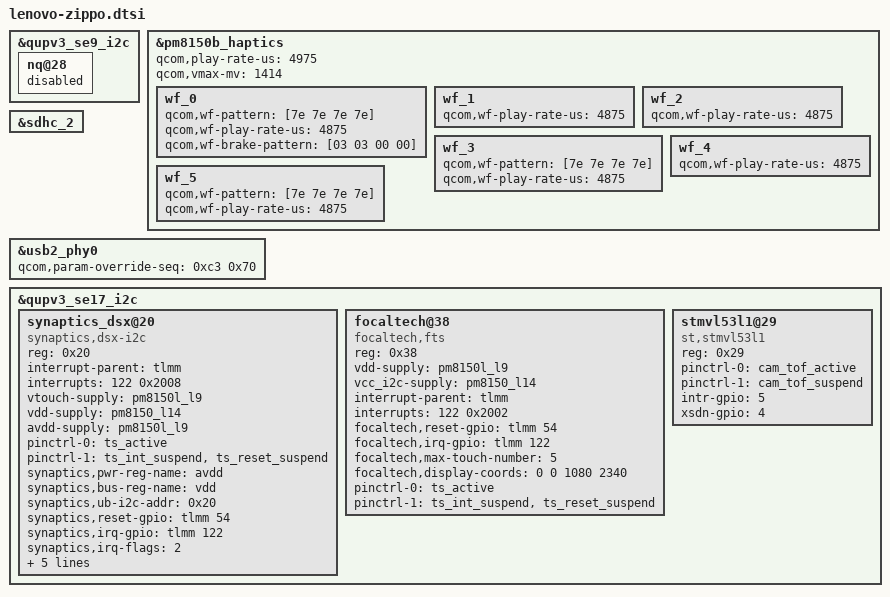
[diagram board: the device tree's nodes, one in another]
/* Copyright (c) 2016-2017, The Linux Foundation. All rights reserved.
 *
 * This program is free software; you can redistribute it and/or modify
 * it under the terms of the GNU General Public License version 2 and
 * only version 2 as published by the Free Software Foundation.
 *
 * This program is distributed in the hope that it will be useful,
 * but WITHOUT ANY WARRANTY; without even the implied warranty of
 * MERCHANTABILITY or FITNESS FOR A PARTICULAR PURPOSE.  See the
 * GNU General Public License for more details.
 */

#include "../common/lenovo-heart-goodixfp.dtsi"

/*Zippo do not support NFC*/
&qupv3_se9_i2c {
	nq@28 {
		status = "disabled";
	};
};

&pm8150b_haptics {
	qcom,play-rate-us = <4975>;
	qcom,vmax-mv = <1414>;

	wf_0 {
		/* CLICK */
		/delete-property/qcom,lra-auto-resonance-disable;
		qcom,wf-pattern = [7e 7e 7e 7e];
		qcom,wf-play-rate-us = <4875>;
		qcom,wf-brake-pattern = [03 03 00 00];
	};
	wf_1 {
		/* DOUBLE CLICK */
		/delete-property/qcom,lra-auto-resonance-disable;
		qcom,wf-play-rate-us = <4875>;
	};
	wf_2 {
		/* TICK */
		/delete-property/qcom,lra-auto-resonance-disable;
		qcom,wf-play-rate-us = <4875>;
	};
	wf_3 {
		/* THUD */
		/delete-property/qcom,lra-auto-resonance-disable;
		qcom,wf-pattern = [7e 7e 7e 7e];
		qcom,wf-play-rate-us = <4875>;
	};
	wf_4 {
		/* POP */
		/delete-property/qcom,lra-auto-resonance-disable;
		qcom,wf-play-rate-us = <4875>;
	};
	wf_5 {
		/* HEAVY CLICK */
		/delete-property/qcom,lra-auto-resonance-disable;
		qcom,wf-pattern = [7e 7e 7e 7e];
		qcom,wf-play-rate-us = <4875>;
	};
};
&sdhc_2 {
	status = "ok";
};

&usb2_phy0 {
	qcom,param-override-seq = <0xc3 0x70>;
};

&qupv3_se17_i2c {
	status = "ok";

	synaptics_dsx@20 {
		compatible = "synaptics,dsx-i2c";
		reg = <0x20>;
		status = "ok";
		interrupt-parent = <&tlmm>;
		interrupts = <122 0x2008>;
		vtouch-supply = <&pm8150l_l9>;
		vdd-supply = <&pm8150_l14>;
		avdd-supply = <&pm8150l_l9>;
		pinctrl-names = "pmx_ts_active","pmx_ts_suspend";
		pinctrl-0 = <&ts_active>;
		pinctrl-1 = <&ts_int_suspend &ts_reset_suspend>;
		synaptics,pwr-reg-name = "avdd";
		synaptics,bus-reg-name = "vdd";
		synaptics,ub-i2c-addr = <0x20>;
		synaptics,reset-gpio = <&tlmm 54 0x0>;
		synaptics,irq-gpio = <&tlmm 122 0x2008>;
		synaptics,irq-flags = <2>; /* 1:trigger rising, 2:trigger falling;*/
		synaptics,irq-on-state = <0>;
		synaptics,power-delay-ms = <200>;
		synaptics,reset-delay-ms = <200>;
		synaptics,reset-on-state = <0>;
		synaptics,reset-active-ms = <20>;
		/* synaptics,swap-axes; */
		/* uncomment and update line below as appropriate if there are 0D buttons */
		/* synaptics,cap-button-codes = <102 158>; */
		/* uncomment and update lines below as appropriate if there are virtual buttons */
		/* synaptics,vir-button-codes = <102 100 900 100 60 158 300 900 100 60>; */
		/* synaptics,max-y-for-2d = <800>; */
	};

	focaltech@38{
		compatible = "focaltech,fts";
		reg = <0x38>;
		status = "ok";
		vdd-supply = <&pm8150l_l9>;
		vcc_i2c-supply = <&pm8150_l14>;
		interrupt-parent = <&tlmm>;
		interrupts = <122 0x2002>;
		focaltech,reset-gpio = <&tlmm 54 0x0>;
		focaltech,irq-gpio = <&tlmm 122 0x2002>;
		focaltech,max-touch-number = <5>;
		focaltech,display-coords =  <0 0 1080 2340>;

		pinctrl-names = "pmx_ts_active","pmx_ts_suspend";
		pinctrl-0 = <&ts_active>;
		pinctrl-1 = <&ts_int_suspend &ts_reset_suspend>;
	};

	stmvl53l1@29{
		compatible = "st,stmvl53l1";
		reg = <0x29>;
		status = "ok";
		//laser-supply = <&pm8009_l5>;
		pinctrl-names = "cam_default", "cam_suspend";
		pinctrl-0 = <&cam_tof_active>;
		pinctrl-1 = <&cam_tof_suspend>;
		intr-gpio = <5>;
		xsdn-gpio = <4>;
		//pwren-gpio = <10>;
	};
};
